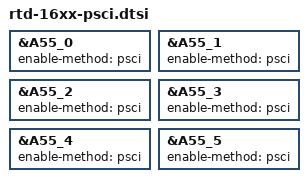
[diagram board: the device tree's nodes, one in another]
#include "rtd-16xx.dtsi"

&A55_0 {
	enable-method = "psci";
};
&A55_1 {
	enable-method = "psci";
	/delete-property/ cpu-release-addr;
};
&A55_2 {
	enable-method = "psci";
	/delete-property/ cpu-release-addr;
};
&A55_3 {
	enable-method = "psci";
	/delete-property/ cpu-release-addr;
};
&A55_4 {
	enable-method = "psci";
	/delete-property/ cpu-release-addr;
};
&A55_5 {
	enable-method = "psci";
	/delete-property/ cpu-release-addr;
};

